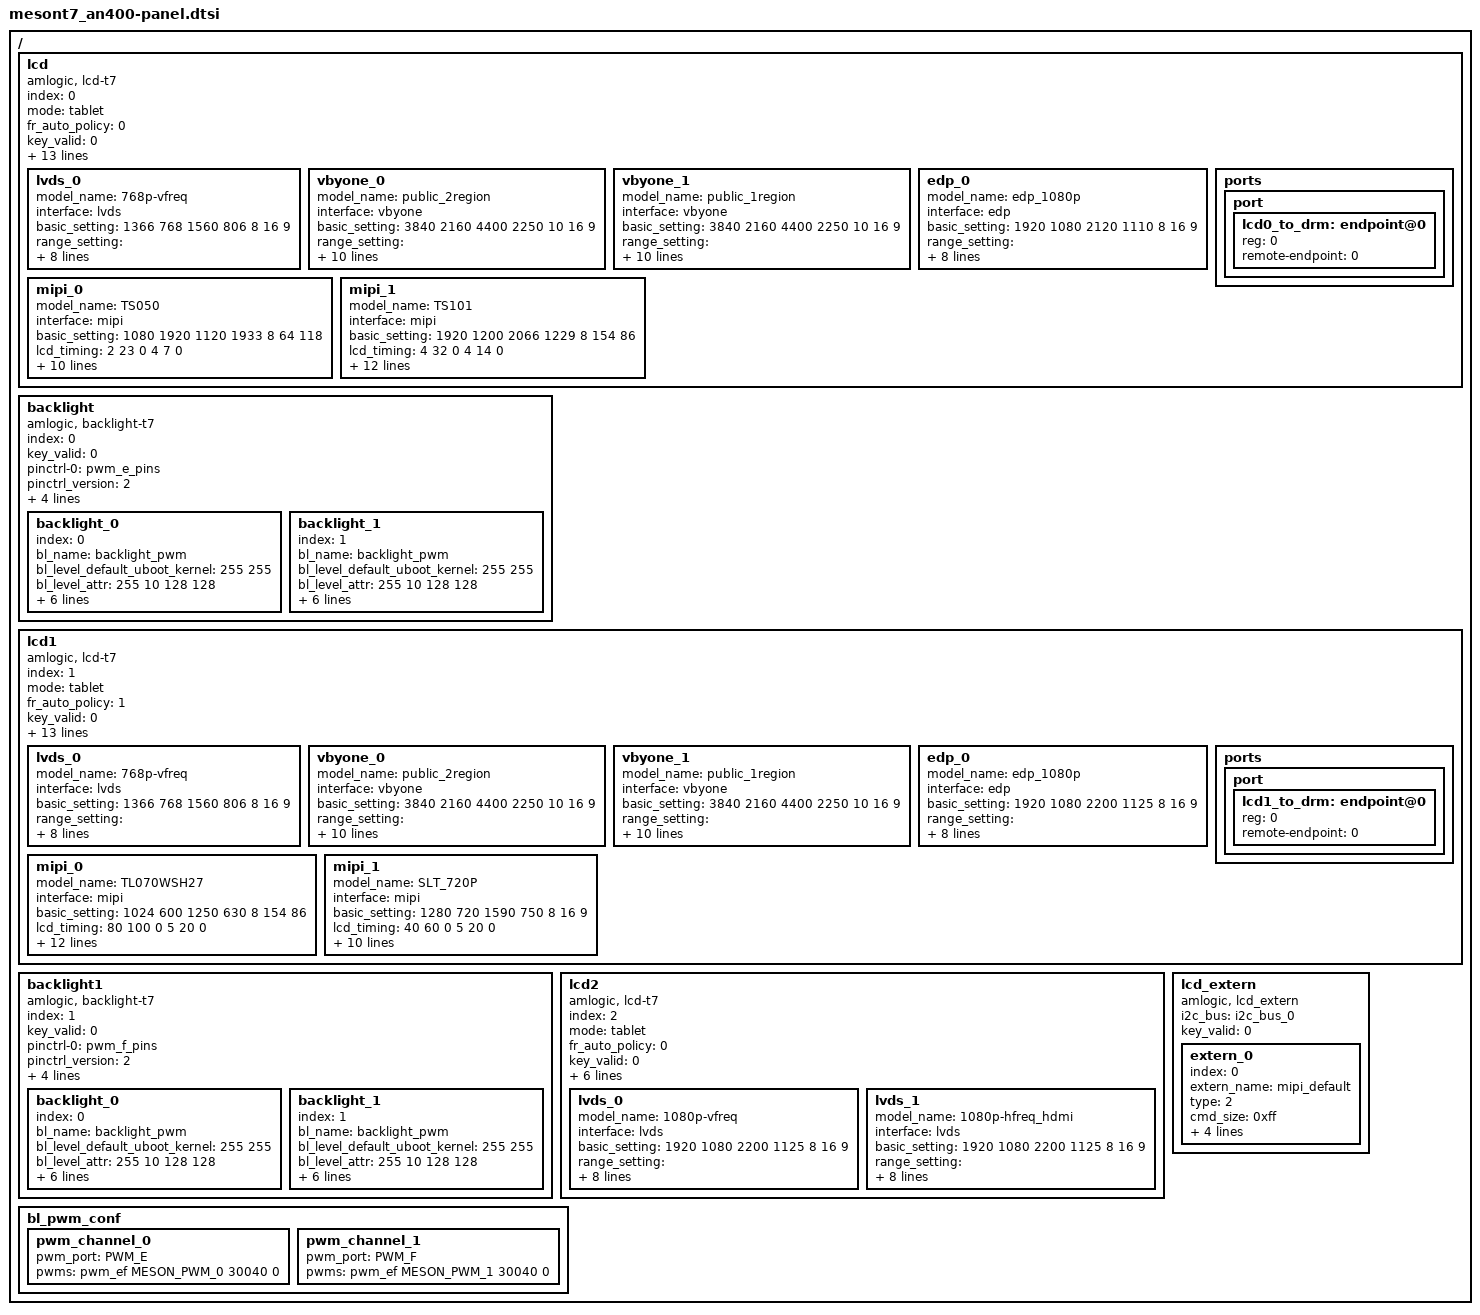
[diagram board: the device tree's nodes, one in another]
// SPDX-License-Identifier: (GPL-2.0+ OR MIT)
/*
 * Copyright (c) 2019 Amlogic, Inc. All rights reserved.
 */

/ {
	lcd:lcd {
		compatible = "amlogic, lcd-t7";
		status = "okay";
		index = <0>;
		mode = "tablet";
		fr_auto_policy = <0>; /* 0=disable, 1=60/50hz, 2=60/50/48hz */
		key_valid = <0>;
		clocks = <&clkc CLKID_MIPI_DSI_A
			&clkc CLKID_DSI0_PHY_GATE
			&clkc CLKID_DSI_A_MEAS_GATE>;
		clock-names = "dsi_host_gate",
			"dsi_phy_gate",
			"dsi_meas";
		reg = <0x0 0xfe018000 0x0 0x60     /* combo dphy */
			0x0 0xfe0b0000 0x0 0x10b0  /* edp_a host */
			0x0 0xfe074000 0x0 0x400   /* mipi_dsi_a host */
			0x0 0xfe014000 0x0 0x200   /* mipi_dsi_a phy */
			0x0 0xfe002000 0x0 0xa0    /* reset */
			0x0 0xfe004000 0x0 0x70>;  /* periphs */
		interrupts = <0 197 1
			0 194 1
			0 82 1
			0 282 1>;
		interrupt-names = "vsync","vsync2","vsync3","vbyone";
		pinctrl-names = "vbyone","vbyone_off","edp","edp_off";
		pinctrl-0 = <&lcd_vbyone_a_pins>;
		pinctrl-1 = <&lcd_vbyone_a_off_pins>;
		pinctrl-2 = <&lcd_edp_a_pins>;
		pinctrl-3 = <&lcd_edp_a_off_pins>;
		pinctrl_version = <2>; /* for uboot */

		/* power type:(0=cpu_gpio, 2=signal, 3=extern, 0xff=ending) */
		/* power index:(gpios_index, or extern_index, 0xff=invalid) */
		/* power value:(0=output low, 1=output high, 2=input) */
		/* power delay:(unit in ms) */
		lcd_cpu-gpios = <&gpio GPIOY_2 GPIO_ACTIVE_HIGH
			&gpio GPIOY_9 GPIO_ACTIVE_HIGH>;
		lcd_cpu_gpio_names = "GPIOY_2","GPIOY_9";

		lvds_0{
			model_name = "768p-vfreq";
			interface = "lvds"; /*lcd_interface(lvds, vbyone)*/
			basic_setting = <
				1366 768 /*h_active, v_active*/
				1560 806 /*h_period, v_period*/
				8      /*lcd_bits*/
				16 9>; /*screen_widht, screen_height*/
			range_setting = <
				1460 2000 /*h_period_min, max */
				784 1015  /*v_period_min, max */
				50000000 85000000>; /*pclk_min, max*/
			lcd_timing = <
				56 64 0   /*hs_width, hs_bp, hs_pol*/
				3  28 0>; /*vs_width, vs_bp, vs_pol*/
			clk_attr = <
				2 /*fr_adj_type
				   *(0=clk, 1=htotal, 2=vtotal, 3=auto_range,
				   * 4=hdmi_mode)
				   */
				15 /*clk_ss_level*/
				1 /*clk_auto_generate*/
				0>; /*pixel_clk(unit in Hz)*/
			lvds_attr = <
				1  /*lvds_repack*/
				0  /*dual_port*/
				0  /*pn_swap*/
				0  /*port_swap*/
				0>; /*lane_reverse*/
			phy_attr=<0x3 0>; /*vswing_level, preem_level*/

			/* power step: type, index, value, delay(ms) */
			power_on_step = <
				0 0 1 50  /*panel power on*/
				2 0 0 0   /*signal enable*/
				0xff 0 0 0>; /*ending*/
			power_off_step = <
				2 0 0 10  /*signal disable*/
				0 0 0 100 /*panel power off*/
				0xff 0 0 0>; /*ending*/
			backlight_index = <0xff>;
		};
		vbyone_0{
			model_name = "public_2region";
			interface = "vbyone"; /*lcd_interface(lvds, vbyone)*/
			basic_setting = <
				3840 2160 /*h_active, v_active*/
				4400 2250 /*h_period, v_period*/
				10     /*lcd_bits */
				16 9>; /*screen_widht, screen_height*/
			range_setting = <
				4240 4800 /*h_period_min, max*/
				2200 2760 /*v_period_min, max*/
				480000000 624000000>; /*pclk_min, max*/
			lcd_timing = <
				33 477 0  /*hs_width, hs_bp, hs_pol*/
				6  65 0>; /*vs_width, vs_bp, vs_pol*/
			clk_attr = <
				2 /*fr_adj_type
				   *(0=clk, 1=htotal, 2=vtotal, 3=auto_range,
				   * 4=hdmi_mode)
				   */
				0 /*clk_ss_level*/
				1 /*clk_auto_generate*/
				0>; /*pixel_clk(unit in Hz)*/
			vbyone_attr = <
				8 /*lane_count*/
				2 /*region_num*/
				4 /*byte_mode*/
				4>; /*color_fmt*/
			vbyone_intr_enable = <
				1 /*vbyone_intr_enable */
				3>; /*vbyone_vsync_intr_enable*/
			phy_attr=<0x7 1>; /* vswing_level, preem_level */
			hw_filter=<0 0>;  /* filter_time, filter_cnt*/

			/* power step: type, index, value, delay(ms) */
			power_on_step = <
				0 0 1 200  /*panel power on*/
				2 0 0 10  /*signal enable*/
				0xff 0 0 0>; /*ending*/
			power_off_step = <
				2 0 0 10 /*signal disable*/
				0 0 0 500 /*panel power off*/
				0xff 0 0 0>; /*ending*/
			backlight_index = <0>;
		};
		vbyone_1{
			model_name = "public_1region";
			interface = "vbyone"; /*lcd_interface(lvds, vbyone)*/
			basic_setting = <
				3840 2160 /*h_active, v_active*/
				4400 2250 /*h_period, v_period*/
				10     /*lcd_bits*/
				16 9>; /*screen_widht, screen_height*/
			range_setting = <
				4240 4800 /*h_period_min, max*/
				2200 2790 /*v_period_min, max*/
				552000000 632000000>; /*pclk_min,max*/
			lcd_timing = <
				33 477 0   /*hs_width, hs_bp, hs_pol*/
				6  65  0>; /*vs_width, vs_bp, vs_pol*/
			clk_attr = <
				2 /*fr_adj_type
				   *(0=clk, 1=htotal, 2=vtotal, 3=auto_range,
				   * 4=hdmi_mode)
				   */
				0 /*clk_ss_level*/
				1 /*clk_auto_generate*/
				0>; /*pixel_clk(unit in Hz)*/
			vbyone_attr = <
				8 /*lane_count*/
				1 /*region_num*/
				4 /*byte_mode*/
				4>; /*color_fmt*/
			vbyone_intr_enable = <
				1   /*vbyone_intr_enable*/
				3>; /*vbyone_vsync_intr_enable*/
			phy_attr=<0x7 1>; /* vswing_level, preem_level */
			hw_filter=<0 0>;  /* filter_time, filter_cnt*/

			/* power step: type, index, value, delay(ms) */
			power_on_step = <
				0 0 1 200  /*panel power on*/
				2 0 0 10 /*signal enable*/
				0xff 0 0 0>; /*ending*/
			power_off_step = <
				2 0 0 10  /*signal disable*/
				0 0 0 500 /*panel power off*/
				0xff 0 0 0>; /*ending*/
			backlight_index = <0xff>;
		};

		edp_0{
			model_name = "edp_1080p";
			interface = "edp"; /*lcd_interface(lvds, vbyone)*/
			basic_setting = <
				1920 1080 /*h_active, v_active*/
				2120 1110 /*h_period, v_period*/
				8      /*lcd_bits*/
				16 9>; /*screen_widht, screen_height*/
			range_setting = <
				2020 2400 /*h_period min, max*/
				1090 1200 /*v_period min, max*/
				132000000 142000000>; /*pclk_min, max*/
			lcd_timing = <
				20 80 0   /*hs_width, hs_bp, hs_pol*/
				10 10 0>; /*vs_width, vs_bp, vs_pol*/
			clk_attr = <
				0 /*fr_adj_type
				   *(0=clk, 1=htotal, 2=vtotal, 3=auto_range,
				   * 4=hdmi_mode)
				   */
				0 /*clk_ss_level */
				1 /*clk_auto_generate*/
				0>; /*pixel_clk(unit in Hz)*/
			edp_attr = <
				2 /*max_lane_count: 1,2,4*/
				1 /*max_link_rate: 0=1.62G, 1=2.7G*/
				0 /*training_mode*/
				0 /*edid_en, auto timing by edid*/
				0 /*reserved */
				0 /*reserved */
				0 /*reserved */
				0 /*reserved */
				0>; /*reserved*/
			phy_attr=<0x5 1>; /*vswing_level, preem_level*/

			/* power step: type, index, value, delay(ms) */
			power_on_step = <
				0 0 1 50  /*panel power on*/
				2 0 0 0   /*signal enable*/
				0xff 0 0 0>; /*ending*/
			power_off_step = <
				2 0 0 10  /*signal disable*/
				0 0 0 200  /*panel power on*/
				0xff 0 0 0>; /*ending*/
			backlight_index = <0x0>;
		};
		
		mipi_0{
			model_name = "TS050";
			interface = "mipi";
			basic_setting = <1080 1920 /*h_active, v_active*/
				1120 1933 /*h_period, v_period*/
				8 /*lcd_bits*/
				64 118>; /*screen_widht, screen_height*/
			lcd_timing = <2 23 0 /*hs_width, hs_bp, hs_pol*/
				4 7 0>; /*vs_width, vs_bp, vs_pol*/
			clk_attr = <0 /*fr_adj_type(0=clk, 1=htotal, 2=vtotal)*/
				0 /*clk_ss_level */
				1 /*clk_auto_generate*/
				120000000>; /*pixel_clk(unit in Hz)*/
			mipi_attr = <4 /*lane_num*/
				1000 /*bit_rate_max(MHz)*/
				0 /*factor(*100, default 0 for auto)*/
				1 /*operation_mode_init(0=video, 1=command)*/
				0 /*operation_mode_display(0=video, 1=command)*/
				2 /*
				   *video_mode_type
				   *(0=sync_pulse,1=sync_event,2=burst)
				   */
				1 /*clk_always_hs(0=disable,1=enable)*/
				0>; /*phy_switch(0=auto,1=standard,2=slow)*/

			/* dsi_init: data_type, num, data... */
			dsi_init_on = <0xff 0>;
			dsi_init_off = <0xff 0>;
			extern_init = <0x0>;
			/* power step: type, index, value, delay(ms) */
			power_on_step = <
				0 0 1 60
				0 1 1 20
				0 1 0 20
				0 1 1 20
				2 0 0 0
				0xff 0 0 0>; /*ending*/
			power_off_step = <
				2 0 0 0
				0 1 0 0
				0 0 0 20
				0xff 0 0 0>; /*ending*/
			backlight_index = <0>;
		};

		mipi_1{
			model_name = "TS101";
			interface = "mipi";
			basic_setting = <1920 1200 /*h_active, v_active*/
				2066 1229 /*h_period, v_period*/
				8 /*lcd_bits*/
				154 86>; /*screen_widht, screen_height*/
			lcd_timing = <4 32 0 /*hs_width, hs_bp, hs_pol*/
				4 14 0>; /*vs_width, vs_bp, vs_pol*/
			clk_attr = <0xff /*fr_adj_type(0=clk, 1=htotal, 2=vtotal)*/
				0 /*clk_ss_level */
				1 /*clk_auto_generate*/
				137112156>; /*pixel_clk(unit in Hz)*/
			mipi_attr = <4 /*lane_num*/
				1000 /*bit_rate_max(MHz)*/
				0 /*factor(*100, default 0 for auto)*/
				1 /*operation_mode_init(0=video, 1=command)*/
				0 /*operation_mode_display(0=video, 1=command)*/
				2 /*
				   *video_mode_type
				   *(0=sync_pulse,1=sync_event,2=burst)
				   */
				1 /*clk_always_hs(0=disable,1=enable)*/
				0>; /*phy_switch(0=auto,1=standard,2=slow)*/

			/* dsi_init: data_type, num, data... */
			dsi_init_on = <0x05 1 0x11
					0xfd 1 20     /*delay(ms)*/
					0x05 1 0x29
					0xfd 1 20     /*delay(ms)*/
					0xff 0>; /*ending*/
			dsi_init_off = <0x05 1 0x28
					0xfd 1 10     /*delay(ms)*/
					0x05 1 0x10
					0xfd 1 10     /*delay(ms)*/
					0xff 0>; /*ending*/
			extern_init = <0xff>; /*0xff for invalid*/

			/* power step: type, index, value, delay(ms) */
			power_on_step = <
				0 0 1 100
				0 1 0 10
				0 1 1 20
				2 0 0 0
				0xff 0 0 0>; /*ending*/
			power_off_step = <
				2 0 0 50
				0 1 0 10
				0 0 0 100
				0xff 0 0 0>; /*ending*/
			backlight_index = <0>;
		};

		ports {
			port {
				#address-cells = <1>;
				#size-cells = <0>;
				lcd0_to_drm: endpoint@0 {
					reg = <0>;
					remote-endpoint = <0>;
				};
			};
		};
	};

	backlight{
		compatible = "amlogic, backlight-t7";
		status = "okay";
		index = <0>;
		key_valid = <0>;
		pinctrl-names = "pwm_on";
		pinctrl-0 = <&pwm_e_pins>;
		pinctrl_version = <2>; /* for uboot */
		interrupts = <0 197 1
			0 194 1
			0 82 1>;
		interrupt-names = "vsync","vsync2","vsync3";
		bl_pwm_config = <&bl_pwm_conf>;

		/* pwm port: PWM_A, PWM_B, PWM_C, PWM_D, PWM_E, PWM_F, PWM_VS*/
		/* power index:(point gpios_index, 0xff=invalid) */
		/* power value:(0=output low, 1=output high, 2=input) */
		/* power delay:(unit in ms) */
		bl-gpios = <&gpio GPIOY_2 GPIO_ACTIVE_HIGH
			&gpio GPIOY_1 GPIO_ACTIVE_HIGH>;
		bl_gpio_names = "GPIOY_2","GPIOY_1";

		backlight_0{
			index = <0>;
			bl_name = "backlight_pwm";
			bl_level_default_uboot_kernel = <255 255>;
			bl_level_attr = <255 10 /*max, min*/
				128 128>; /*mid, mid_mapping*/
			bl_ctrl_method = <1>; /*1=pwm,2=pwm_combo*/
			bl_power_attr = <0 /*en_gpio_index*/
				1 0 /*on_value, off_value*/
				200 200>; /*on_delay(ms), off_delay(ms)*/
			bl_pwm_port = "PWM_E";
			bl_pwm_attr = <1 /*pwm_method(0=negative, 1=positvie)*/
				180 /*pwm_freq(pwm:Hz, pwm_vs:multiple of vs)*/
				100 25>; /*duty_max(%), duty_min(%)*/
			bl_pwm_power = <1 0 /*pwm_gpio_index, pwm_gpio_off*/
				10 10>; /*pwm_on_delay(ms), pwm_off_delay(ms)*/
			en_sequence_reverse = <0>; /* 1 for reverse */
		};

		backlight_1{
			index = <1>;
			bl_name = "backlight_pwm";
			bl_level_default_uboot_kernel = <255 255>;
			bl_level_attr = <255 10 /*max, min*/
				128 128>; /*mid, mid_mapping*/
			bl_ctrl_method = <1>; /*1=pwm,2=pwm_combo*/
			bl_power_attr = <0 /*en_gpio_index*/
				1 0 /*on_value, off_value*/
				200 200>; /*on_delay(ms), off_delay(ms)*/
			bl_pwm_port = "PWM_E";
			bl_pwm_attr = <0 /*pwm_method(0=negative, 1=positvie)*/
				180 /*pwm_freq(pwm:Hz, pwm_vs:multiple of vs)*/
				100 25>; /*duty_max(%), duty_min(%)*/
			bl_pwm_power = <1 0 /*pwm_gpio_index, pwm_gpio_off*/
				10 10>; /*pwm_on_delay(ms), pwm_off_delay(ms)*/
			en_sequence_reverse = <0>; /* 1 for reverse */
		};
	};

	lcd1:lcd1 {
		compatible = "amlogic, lcd-t7";
		status = "okay";
		index = <1>;
		mode = "tablet";
		fr_auto_policy = <1>; /* 0=disable, 1=60/50hz, 2=60/50/48hz */
		key_valid = <0>;
		clocks = <&clkc CLKID_MIPI_DSI_B
			&clkc CLKID_DSI1_PHY_GATE
			&clkc CLKID_DSI_B_MEAS_GATE>;
		clock-names = "dsi_host_gate",
			"dsi_phy_gate",
			"dsi_meas";
		reg = <0x0 0xfe018000 0x0 0x60     /* combo dphy */
			0x0 0xfe0b2000 0x0 0x10b0  /* edp_b host */
			0x0 0xfe072000 0x0 0x400   /* mipi_dsi_b host */
			0x0 0xfe016000 0x0 0x200   /* mipi_dsi_b phy */
			0x0 0xfe002000 0x0 0xa0    /* reset */
			0x0 0xfe004000 0x0 0x70>;  /* periphs */
		interrupts = <0 197 1
			0 194 1
			0 82 1
			0 283 1>;
		interrupt-names = "vsync","vsync2","vsync3","vbyone";
		pinctrl-names = "vbyone","vbyone_off","edp","edp_off";
		pinctrl-0 = <&lcd_vbyone_b_pins>;
		pinctrl-1 = <&lcd_vbyone_b_off_pins>;
		pinctrl-2 = <&lcd_edp_b_pins>;
		pinctrl-3 = <&lcd_edp_b_off_pins>;
		pinctrl_version = <2>; /* for uboot */

		/* power type:(0=cpu_gpio, 2=signal, 3=extern, 0xff=ending) */
		/* power index:(gpios_index, or extern_index, 0xff=invalid) */
		/* power value:(0=output low, 1=output high, 2=input) */
		/* power delay:(unit in ms) */
		lcd_cpu-gpios = <&gpio GPIOT_19 GPIO_ACTIVE_HIGH
			&gpio GPIOY_6 GPIO_ACTIVE_HIGH>;
		lcd_cpu_gpio_names = "GPIOT_19","GPIOY_6";

		lvds_0{
			model_name = "768p-vfreq";
			interface = "lvds"; /*lcd_interface(lvds, vbyone)*/
			basic_setting = <
				1366 768 /*h_active, v_active*/
				1560 806 /*h_period, v_period*/
				8      /*lcd_bits*/
				16 9>; /*screen_widht, screen_height*/
			range_setting = <
				1460 2000 /*h_period_min, max */
				784 1015  /*v_period_min, max */
				50000000 85000000>; /*pclk_min, max*/
			lcd_timing = <
				56 64 0   /*hs_width, hs_bp, hs_pol*/
				3  28 0>; /*vs_width, vs_bp, vs_pol*/
			clk_attr = <
				2 /*fr_adj_type
				   *(0=clk, 1=htotal, 2=vtotal, 3=auto_range,
				   * 4=hdmi_mode)
				   */
				15 /*clk_ss_level*/
				1 /*clk_auto_generate*/
				0>; /*pixel_clk(unit in Hz)*/
			lvds_attr = <
				1  /*lvds_repack*/
				0  /*dual_port*/
				0  /*pn_swap*/
				0  /*port_swap*/
				0>; /*lane_reverse*/
			phy_attr=<0x3 0>; /*vswing_level, preem_level*/

			/* power step: type, index, value, delay(ms) */
			power_on_step = <
				0 0 1 50  /*panel power on*/
				2 0 0 0   /*signal enable*/
				0xff 0 0 0>; /*ending*/
			power_off_step = <
				2 0 0 10  /*signal disable*/
				0 0 0 100 /*panel power off*/
				0xff 0 0 0>; /*ending*/
			backlight_index = <0xff>;
		};
		vbyone_0{
			model_name = "public_2region";
			interface = "vbyone"; /*lcd_interface(lvds, vbyone)*/
			basic_setting = <
				3840 2160 /*h_active, v_active*/
				4400 2250 /*h_period, v_period*/
				10     /*lcd_bits */
				16 9>; /*screen_widht, screen_height*/
			range_setting = <
				4240 4800 /*h_period_min, max*/
				2200 2760 /*v_period_min, max*/
				480000000 624000000>; /*pclk_min, max*/
			lcd_timing = <
				33 477 0  /*hs_width, hs_bp, hs_pol*/
				6  65 0>; /*vs_width, vs_bp, vs_pol*/
			clk_attr = <
				2 /*fr_adj_type
				   *(0=clk, 1=htotal, 2=vtotal, 3=auto_range,
				   * 4=hdmi_mode)
				   */
				0 /*clk_ss_level*/
				1 /*clk_auto_generate*/
				0>; /*pixel_clk(unit in Hz)*/
			vbyone_attr = <
				8 /*lane_count*/
				2 /*region_num*/
				4 /*byte_mode*/
				4>; /*color_fmt*/
			vbyone_intr_enable = <
				1 /*vbyone_intr_enable */
				3>; /*vbyone_vsync_intr_enable*/
			phy_attr=<0x7 1>; /* vswing_level, preem_level */
			hw_filter=<0 0>;  /* filter_time, filter_cnt*/

			/* power step: type, index, value, delay(ms) */
			power_on_step = <
				0 0 1 200  /*panel power on*/
				2 0 0 10  /*signal enable*/
				0xff 0 0 0>; /*ending*/
			power_off_step = <
				2 0 0 10 /*signal disable*/
				0 0 0 500  /*panel power off*/
				0xff 0 0 0>; /*ending*/
			backlight_index = <0x0>;
		};
		vbyone_1{
			model_name = "public_1region";
			interface = "vbyone"; /*lcd_interface(lvds, vbyone)*/
			basic_setting = <
				3840 2160 /*h_active, v_active*/
				4400 2250 /*h_period, v_period*/
				10     /*lcd_bits*/
				16 9>; /*screen_widht, screen_height*/
			range_setting = <
				4320 4800 /*h_period_min, max*/
				2200 2760 /*v_period_min, max*/
				503316480 654311424>; /*pclk_min,max*/
			lcd_timing = <
				33 477 0   /*hs_width, hs_bp, hs_pol*/
				6  65  0>; /*vs_width, vs_bp, vs_pol*/
			clk_attr = <
				2 /*fr_adj_type
				   *(0=clk, 1=htotal, 2=vtotal, 3=auto_range,
				   * 4=hdmi_mode)
				   */
				0 /*clk_ss_level*/
				1 /*clk_auto_generate*/
				0>; /*pixel_clk(unit in Hz)*/
			vbyone_attr = <
				8 /*lane_count*/
				1 /*region_num*/
				4 /*byte_mode*/
				4>; /*color_fmt*/
			vbyone_intr_enable = <
				1   /*vbyone_intr_enable*/
				3>; /*vbyone_vsync_intr_enable*/
			phy_attr=<0x7 1>; /* vswing_level, preem_level */
			hw_filter=<0 0>;  /* filter_time, filter_cnt*/

			/* power step: type, index, value, delay(ms) */
			power_on_step = <
				0 0 1 200  /*panel power on*/
				2 0 0 10 /*signal enable*/
				0xff 0 0 0>; /*ending*/
			power_off_step = <
				2 0 0 10  /*signal disable*/
				0 0 0 500  /*panel power off*/
				0xff 0 0 0>; /*ending*/
			backlight_index = <0x0>;
		};

		edp_0{
			model_name = "edp_1080p";
			interface = "edp"; /*lcd_interface(lvds, vbyone)*/
			basic_setting = <
				1920 1080 /*h_active, v_active*/
				2200 1125 /*h_period, v_period*/
				8      /*lcd_bits*/
				16 9>; /*screen_widht, screen_height*/
			range_setting = <
				2080 2720 /*h_period min, max*/
				1100 1380 /*v_period min, max*/
				133940000 156000000>; /*pclk_min, max*/
			lcd_timing = <
				44 148 0   /*hs_width, hs_bp, hs_pol*/
				5  30  0>; /*vs_width, vs_bp, vs_pol*/
			clk_attr = <
				0 /*fr_adj_type
				   *(0=clk, 1=htotal, 2=vtotal, 3=auto_range,
				   * 4=hdmi_mode)
				   */
				0 /*clk_ss_level */
				1 /*clk_auto_generate*/
				0>; /*pixel_clk(unit in Hz)*/
			edp_attr = <
				2 /*max_lane_count: 1,2,4*/
				1 /*max_link_rate: 0=1.62G, 1=2.7G*/
				0 /*training_mode*/
				0 /*reserved*/
				0 /*reserved */
				0 /*reserved */
				0 /*reserved */
				0 /*reserved */
				0>; /*reserved*/
			phy_attr=<0x5 1>; /*vswing_level, preem_level*/

			/* power step: type, index, value, delay(ms) */
			power_on_step = <
				0 0 1 50  /*panel power on*/
				2 0 0 0   /*signal enable*/
				0xff 0 0 0>; /*ending*/
			power_off_step = <
				2 0 0 10  /*signal disable*/
				0 0 0 200  /*panel power on*/
				0xff 0 0 0>; /*ending*/
			backlight_index = <0x0>;
		};
		mipi_0{
			model_name = "TL070WSH27";
			interface = "mipi";
			basic_setting = <1024 600 /*h_active, v_active*/
				1250 630 /*h_period, v_period*/
				8 /*lcd_bits*/
				154 86>; /*screen_widht, screen_height*/
			lcd_timing = <80 100 0 /*hs_width, hs_bp, hs_pol*/
				5 20 0>; /*vs_width, vs_bp, vs_pol*/
			clk_attr = <0 /*fr_adj_type(0=clk, 1=htotal, 2=vtotal)*/
				0 /*clk_ss_level */
				1 /*clk_auto_generate*/
				47250000>; /*pixel_clk(unit in Hz)*/
			mipi_attr = <4 /*lane_num*/
				300 /*bit_rate_max(MHz)*/
				0 /*factor(*100, default 0 for auto)*/
				1 /*operation_mode_init(0=video, 1=command)*/
				0 /*operation_mode_display(0=video, 1=command)*/
				2 /*
				   *video_mode_type
				   *(0=sync_pulse,1=sync_event,2=burst)
				   */
				1 /*clk_always_hs(0=disable,1=enable)*/
				0>; /*phy_switch(0=auto,1=standard,2=slow)*/

			/* dsi_init: data_type, num, data... */
			dsi_init_on = <0x05 1 0x11
					0xfd 1 20     /*delay(ms)*/
					0x05 1 0x29
					0xfd 1 20     /*delay(ms)*/
					0xff 0>; /*ending*/
			dsi_init_off = <0x05 1 0x28
					0xfd 1 10     /*delay(ms)*/
					0x05 1 0x10
					0xfd 1 10     /*delay(ms)*/
					0xff 0>; /*ending*/
			extern_init = <0xff>; /*0xff for invalid*/

			/* power step: type, index, value, delay(ms) */
			power_on_step = <
				0 0 1 100
				0 1 0 10
				0 1 1 20
				2 0 0 0
				0xff 0 0 0>; /*ending*/
			power_off_step = <
				2 0 0 50
				0 1 0 10
				0 0 0 100
				0xff 0 0 0>; /*ending*/
			backlight_index = <0x1>;
		};
		mipi_1{
			model_name = "SLT_720P";
			interface = "mipi";
			basic_setting = <1280 720 /*h_active, v_active*/
				1590 750 /*h_period, v_period*/
				8 /*lcd_bits*/
				16 9>; /*screen_widht, screen_height*/
			lcd_timing = <40 60 0 /*hs_width,hs_bp,hs_pol*/
				5 20 0>; /*vs_width,vs_bp,vs_pol*/
			clk_attr = <0 /*fr_adj_type(0=clock,1=htotal,2=vtotal)*/
				0 /*clk_ss_level*/
				1 /*clk_auto_generate*/
				74250000>; /*pixel_clk(unit in Hz)*/
			mipi_attr = <4 /*lane_num*/
				550 /*bit_rate_max(MHz)*/
				0 /*factor(*100, default 0 for auto)*/
				1 /*operation_mode_init(0=video, 1=command)*/
				0 /*operation_mode_display(0=video, 1=command)*/
				0 /*
				   *video_mode_type
				   *(0=sync_pulse,1=sync_event,2=burst)
				   */
				1 /*clk_always_hs(0=disable,1=enable)*/
				0>; /*phy_switch(0=auto,1=standard,2=slow)*/
				/* dsi_init: data_type, num, data... */
			dsi_init_on = <
				0x05 1 0x11
				0xff 200
				0x05 1 0x29
				0xff 20
				0xff 0xff>; /* ending flag */
			dsi_init_off = <
				0x05 1 0x28
				0xff 10
				0x05 1 0x10
				0xff 10
				0xff 0xff>; /* ending flag */
				/* extern_init: 0xff for invalid */
			extern_init = <0xff>;
				/* power step: type,index,value,delay(ms) */
			power_on_step = <
					3 7 0 100
					2 0 0 0
					0xff 0 0 0>;
			power_off_step = <
					2 0 0 0
					0xff 0 0 0>;
			backlight_index = <0xff>;
		};
		ports {
			port {
				#address-cells = <1>;
				#size-cells = <0>;
				lcd1_to_drm: endpoint@0 {
					reg = <0>;
					remote-endpoint = <0>;
				};
			};
		};
	};

	backlight1{
		compatible = "amlogic, backlight-t7";
		status = "okay";
		index = <1>;
		key_valid = <0>;
		pinctrl-names = "pwm_on";
		pinctrl-0 = <&pwm_f_pins>;
		pinctrl_version = <2>; /* for uboot */
		interrupts = <0 197 1
			0 194 1
			0 82 1>;
		interrupt-names = "vsync","vsync2","vsync3";
		bl_pwm_config = <&bl_pwm_conf>;

		/* pwm port: PWM_A, PWM_B, PWM_C, PWM_D, PWM_E, PWM_F, PWM_VS*/
		/* power index:(point gpios_index, 0xff=invalid) */
		/* power value:(0=output low, 1=output high, 2=input) */
		/* power delay:(unit in ms) */
		bl-gpios = <&gpio GPIOT_18 GPIO_ACTIVE_HIGH
			&gpio GPIOY_8 GPIO_ACTIVE_HIGH>;
		bl_gpio_names = "GPIOT_18","GPIOY_8";

		backlight_0{
			index = <0>;
			bl_name = "backlight_pwm";
			bl_level_default_uboot_kernel = <255 255>;
			bl_level_attr = <255 10 /*max, min*/
				128 128>; /*mid, mid_mapping*/
			bl_ctrl_method = <1>; /*1=pwm,2=pwm_combo*/
			bl_power_attr = <0 /*en_gpio_index*/
				1 0 /*on_value, off_value*/
				200 200>; /*on_delay(ms), off_delay(ms)*/
			bl_pwm_port = "PWM_F";
			bl_pwm_attr = <1 /*pwm_method(0=negative, 1=positvie)*/
				180 /*pwm_freq(pwm:Hz, pwm_vs:multiple of vs)*/
				100 25>; /*duty_max(%), duty_min(%)*/
			bl_pwm_power = <1 0 /*pwm_gpio_index, pwm_gpio_off*/
				10 10>; /*pwm_on_delay(ms), pwm_off_delay(ms)*/
			en_sequence_reverse = <0>; /* 1 for reverse */
		};

		backlight_1{
			index = <1>;
			bl_name = "backlight_pwm";
			bl_level_default_uboot_kernel = <255 255>;
			bl_level_attr = <255 10 /*max, min*/
				128 128>; /*mid, mid_mapping*/
			bl_ctrl_method = <1>; /*1=pwm,2=pwm_combo*/
			bl_power_attr = <0 /*en_gpio_index*/
				1 0 /*on_value, off_value*/
				200 200>; /*on_delay(ms), off_delay(ms)*/
			bl_pwm_port = "PWM_F";
			bl_pwm_attr = <0 /*pwm_method(0=negative, 1=positvie)*/
				180 /*pwm_freq(pwm:Hz, pwm_vs:multiple of vs)*/
				100 25>; /*duty_max(%), duty_min(%)*/
			bl_pwm_power = <1 0 /*pwm_gpio_index, pwm_gpio_off*/
				10 10>; /*pwm_on_delay(ms), pwm_off_delay(ms)*/
			en_sequence_reverse = <0>; /* 1 for reverse */
		};
	};

	lcd2:lcd2 {
		compatible = "amlogic, lcd-t7";
		status = "okay";
		index = <2>;
		mode = "tablet";
		fr_auto_policy = <0>; /* 0=disable, 1=60/50hz, 2=60/50/48hz */
		key_valid = <0>;
		reg = <0x0 0xfe018000 0x0 0x60     /* combo dphy */
			0x0 0xfe0b0000 0x0 0x10b0  /* edp_a host */
			0x0 0xfe074000 0x0 0x400   /* mipi_dsi_a host */
			0x0 0xfe014000 0x0 0x200   /* mipi_dsi_a phy */
			0x0 0xfe002000 0x0 0xa0    /* reset */
			0x0 0xfe004000 0x0 0x70>;  /* periphs */
		interrupts = <0 197 1
			0 194 1
			0 82 1>;
		interrupt-names = "vsync","vsync2","vsync3";
		pinctrl_version = <2>; /* for uboot */

		/* power type:(0=cpu_gpio, 2=signal, 3=extern, 0xff=ending) */
		/* power index:(gpios_index, or extern_index, 0xff=invalid) */
		/* power value:(0=output low, 1=output high, 2=input) */
		/* power delay:(unit in ms) */
		lcd_cpu-gpios = <&gpio GPIOY_14 GPIO_ACTIVE_HIGH>;
		lcd_cpu_gpio_names = "GPIOY_14";

		lvds_0{
			model_name = "1080p-vfreq";
			interface = "lvds"; /*lcd_interface(lvds, vbyone)*/
			basic_setting = <
				1920 1080 /*h_active, v_active*/
				2200 1125 /*h_period, v_period*/
				8      /*lcd_bits */
				16 9>; /*screen_widht, screen_height*/
			range_setting = <
				2060 2650  /*h_period_min,max*/
				1100 1480  /*v_period_min,max*/
				120000000 160000000>; /*pclk_min,max*/
			lcd_timing = <
				44 148 0  /*hs_width, hs_bp, hs_pol*/
				5  30 0>; /*vs_width, vs_bp, vs_pol*/
			clk_attr = <
				2 /*fr_adj_type
				   *(0=clk, 1=htotal, 2=vtotal, 3=auto_range,
				   * 4=hdmi_mode)
				   */
				0 /*clk_ss_level*/
				1 /*clk_auto_generate*/
				0>; /*pixel_clk(unit in Hz)*/
			lvds_attr = <
				1  /*lvds_repack*/
				1  /*dual_port*/
				0  /*pn_swap*/
				0  /*port_swap*/
				0>; /*lane_reverse*/
			phy_attr=<0x3 0>; /*vswing_level, preem_level*/

			/* power step: type, index, value, delay(ms) */
			power_on_step = <
				0 0 1 50  /*panel power on*/
				2 0 0 0   /*signal enable*/
				0xff 0 0 0>; /*ending*/
			power_off_step = <
				2 0 0 10  /*signal disable*/
				0 0 0 100  /*panel power off*/
				0xff 0 0 0>; /*ending*/
			backlight_index = <0xff>;
		};
		lvds_1{
			model_name = "1080p-hfreq_hdmi";
			interface = "lvds"; /*lcd_interface(lvds, vbyone)*/
			basic_setting = <
				1920 1080 /*h_active, v_active*/
				2200 1125 /*h_period, v_period*/
				8      /*lcd_bits*/
				16 9>; /*screen_widht, screen_height*/
			range_setting = <
				2080 2720 /*h_period min, max*/
				1100 1380 /*v_period min, max*/
				133940000 156000000>; /*pclk_min, max*/
			lcd_timing = <
				44 148 0   /*hs_width, hs_bp, hs_pol*/
				5  30  0>; /*vs_width, vs_bp, vs_pol*/
			clk_attr = <
				4 /*fr_adj_type
				   *(0=clk, 1=htotal, 2=vtotal, 3=auto_range,
				   * 4=hdmi_mode)
				   */
				0 /*clk_ss_level */
				1 /*clk_auto_generate*/
				0>; /*pixel_clk(unit in Hz)*/
			lvds_attr = <
				1 /*lvds_repack*/
				1 /*dual_port*/
				0 /*pn_swap*/
				0 /*port_swap*/
				0>; /*lane_reverse*/
			phy_attr=<0x3 0>; /*vswing_level, preem_level*/

			/* power step: type, index, value, delay(ms) */
			power_on_step = <
				0 0 1 50  /*panel power on*/
				2 0 0 0   /*signal enable*/
				0xff 0 0 0>; /*ending*/
			power_off_step = <
				2 0 0 10  /*signal disable*/
				0 0 0 100  /*panel power off*/
				0xff 0 0 0>; /*ending*/
			backlight_index = <0xff>;
		};
	};

	bl_pwm_conf:bl_pwm_conf{
		pwm_channel_0 {
			pwm_port = "PWM_E";
			pwms = <&pwm_ef MESON_PWM_0 30040 0>;
		};
		pwm_channel_1 {
			pwm_port = "PWM_F";
			pwms = <&pwm_ef MESON_PWM_1 30040 0>;
		};
	};
	
	lcd_extern{
		compatible = "amlogic, lcd_extern";
		status = "okay";
		i2c_bus = "i2c_bus_0";
		key_valid = <0>;

		extern_0{
			index = <0>;
			extern_name = "mipi_default";/*default*/
			status = "okay";
			type = <2>; /* 0=i2c, 1=spi, 2=mipi */
			cmd_size = <0xff>;
			init_on = <
				0x15 2	0xFF 0x05
				0x15 2	0xFB 0x01
				0x15 2	0xC5 0x01
				0xfd 1 120 /* delay 100ms */

				0x15 2 0xFF 0xEE
				0x15 2 0xFB 0x01
				0x15 2 0x1F 0x45
				0x15 2 0x24 0x4F
				0x15 2 0x38 0xC8
				0x15 2 0x39 0x27
				0x15 2 0x1E 0x77
				0x15 2 0x1D 0x0F
				0x15 2 0x7E 0x71
				0x15 2 0x7C 0x03
				0x15 2 0xFF 0x00
				0x15 2 0xFB 0x01
				0x15 2 0x35 0x01
				0x15 2 0xFF 0x01
				0x15 2 0xFB 0x01
				0x15 2 0x00 0x01
				0x15 2 0x01 0x55
				0x15 2 0x02 0x40
				0x15 2 0x05 0x40
				0x15 2 0x06 0x4A
				0x15 2 0x07 0x24
				0x15 2 0x08 0x0C
				0x15 2 0x0B 0x7D
				0x15 2 0x0C 0x7D
				0x15 2 0x0E 0xB0
				0x15 2 0x0F 0xAE
				0x15 2 0x11 0x10
				0x15 2 0x12 0x10
				0x15 2 0x13 0x03
				0x15 2 0x14 0x4A
				0x15 2 0x15 0x12
				0x15 2 0x16 0x12
				0x15 2 0x18 0x00
				0x15 2 0x19 0x77
				0x15 2 0x1A 0x55
				0x15 2 0x1B 0x13
				0x15 2 0x1C 0x00
				0x15 2 0x1D 0x00
				0x15 2 0x1E 0x13
				0x15 2 0x1F 0x00
				0x15 2 0x23 0x00
				0x15 2 0x24 0x00
				0x15 2 0x25 0x00
				0x15 2 0x26 0x00
				0x15 2 0x27 0x00
				0x15 2 0x28 0x00
				0x15 2 0x35 0x00
				0x15 2 0x66 0x00
				0x15 2 0x58 0x82
				0x15 2 0x59 0x02
				0x15 2 0x5A 0x02
				0x15 2 0x5B 0x02
				0x15 2 0x5C 0x82
				0x15 2 0x5D 0x82
				0x15 2 0x5E 0x02
				0x15 2 0x5F 0x02
				0x15 2 0x72 0x31
				0x15 2 0xFF 0x05
				0x15 2 0xFB 0x01
				0x15 2 0x00 0x01
				0x15 2 0x01 0x0B
				0x15 2 0x02 0x0C
				0x15 2 0x03 0x09
				0x15 2 0x04 0x0A
				0x15 2 0x05 0x00
				0x15 2 0x06 0x0F
				0x15 2 0x07 0x10
				0x15 2 0x08 0x00
				0x15 2 0x09 0x00
				0x15 2 0x0A 0x00
				0x15 2 0x0B 0x00
				0x15 2 0x0C 0x00
				0x15 2 0x0D 0x13
				0x15 2 0x0E 0x15
				0x15 2 0x0F 0x17
				0x15 2 0x10 0x01
				0x15 2 0x11 0x0B
				0x15 2 0x12 0x0C
				0x15 2 0x13 0x09
				0x15 2 0x14 0x0A
				0x15 2 0x15 0x00
				0x15 2 0x16 0x0F
				0x15 2 0x17 0x10
				0x15 2 0x18 0x00
				0x15 2 0x19 0x00
				0x15 2 0x1A 0x00
				0x15 2 0x1B 0x00
				0x15 2 0x1C 0x00
				0x15 2 0x1D 0x13
				0x15 2 0x1E 0x15
				0x15 2 0x1F 0x17
				0x15 2 0x20 0x00
				0x15 2 0x21 0x03
				0x15 2 0x22 0x01
				0x15 2 0x23 0x40
				0x15 2 0x24 0x40
				0x15 2 0x25 0xED
				0x15 2 0x29 0x58
				0x15 2 0x2A 0x12
				0x15 2 0x2B 0x01
				0x15 2 0x4B 0x06
				0x15 2 0x4C 0x11
				0x15 2 0x4D 0x20
				0x15 2 0x4E 0x02
				0x15 2 0x4F 0x02
				0x15 2 0x50 0x20
				0x15 2 0x51 0x61
				0x15 2 0x52 0x01
				0x15 2 0x53 0x63
				0x15 2 0x54 0x77
				0x15 2 0x55 0xED
				0x15 2 0x5B 0x00
				0x15 2 0x5C 0x00
				0x15 2 0x5D 0x00
				0x15 2 0x5E 0x00
				0x15 2 0x5F 0x15
				0x15 2 0x60 0x75
				0x15 2 0x61 0x00
				0x15 2 0x62 0x00
				0x15 2 0x63 0x00
				0x15 2 0x64 0x00
				0x15 2 0x65 0x00
				0x15 2 0x66 0x00
				0x15 2 0x67 0x00
				0x15 2 0x68 0x04
				0x15 2 0x69 0x00
				0x15 2 0x6A 0x00
				0x15 2 0x6C 0x40
				0x15 2 0x75 0x01
				0x15 2 0x76 0x01
				0x15 2 0x7A 0x80
				0x15 2 0x7B 0xA3
				0x15 2 0x7C 0xD8
				0x15 2 0x7D 0x60
				0x15 2 0x7F 0x15
				0x15 2 0x80 0x81
				0x15 2 0x83 0x05
				0x15 2 0x93 0x08
				0x15 2 0x94 0x10
				0x15 2 0x8A 0x00
				0x15 2 0x9B 0x0F
				0x15 2 0xEA 0xFF
				0x15 2 0xEC 0x00
				0x15 2 0xFF 0x01
				0x15 2 0xFB 0x01
				0x15 2 0x75 0x00
				0x15 2 0x76 0xDF
				0x15 2 0x77 0x00
				0x15 2 0x78 0xE4
				0x15 2 0x79 0x00
				0x15 2 0x7A 0xED
				0x15 2 0x7B 0x00
				0x15 2 0x7C 0xF6
				0x15 2 0x7D 0x00
				0x15 2 0x7E 0xFF
				0x15 2 0x7F 0x01
				0x15 2 0x80 0x07
				0x15 2 0x81 0x01
				0x15 2 0x82 0x10
				0x15 2 0x83 0x01
				0x15 2 0x84 0x18
				0x15 2 0x85 0x01
				0x15 2 0x86 0x20
				0x15 2 0x87 0x01
				0x15 2 0x88 0x3D
				0x15 2 0x89 0x01
				0x15 2 0x8A 0x56
				0x15 2 0x8B 0x01
				0x15 2 0x8C 0x84
				0x15 2 0x8D 0x01
				0x15 2 0x8E 0xAB
				0x15 2 0x8F 0x01
				0x15 2 0x90 0xEC
				0x15 2 0x91 0x02
				0x15 2 0x92 0x22
				0x15 2 0x93 0x02
				0x15 2 0x94 0x23
				0x15 2 0x95 0x02
				0x15 2 0x96 0x55
				0x15 2 0x97 0x02
				0x15 2 0x98 0x8B
				0x15 2 0x99 0x02
				0x15 2 0x9A 0xAF
				0x15 2 0x9B 0x02
				0x15 2 0x9C 0xDF
				0x15 2 0x9D 0x03
				0x15 2 0x9E 0x01
				0x15 2 0x9F 0x03
				0x15 2 0xA0 0x2C
				0x15 2 0xA2 0x03
				0x15 2 0xA3 0x39
				0x15 2 0xA4 0x03
				0x15 2 0xA5 0x47
				0x15 2 0xA6 0x03
				0x15 2 0xA7 0x56
				0x15 2 0xA9 0x03
				0x15 2 0xAA 0x66
				0x15 2 0xAB 0x03
				0x15 2 0xAC 0x76
				0x15 2 0xAD 0x03
				0x15 2 0xAE 0x85
				0x15 2 0xAF 0x03
				0x15 2 0xB0 0x90
				0x15 2 0xB1 0x03
				0x15 2 0xB2 0xCB
				0x15 2 0xB3 0x00
				0x15 2 0xB4 0xDF
				0x15 2 0xB5 0x00
				0x15 2 0xB6 0xE4
				0x15 2 0xB7 0x00
				0x15 2 0xB8 0xED
				0x15 2 0xB9 0x00
				0x15 2 0xBA 0xF6
				0x15 2 0xBB 0x00
				0x15 2 0xBC 0xFF
				0x15 2 0xBD 0x01
				0x15 2 0xBE 0x07
				0x15 2 0xBF 0x01
				0x15 2 0xC0 0x10
				0x15 2 0xC1 0x01
				0x15 2 0xC2 0x18
				0x15 2 0xC3 0x01
				0x15 2 0xC4 0x20
				0x15 2 0xC5 0x01
				0x15 2 0xC6 0x3D
				0x15 2 0xC7 0x01
				0x15 2 0xC8 0x56
				0x15 2 0xC9 0x01
				0x15 2 0xCA 0x84
				0x15 2 0xCB 0x01
				0x15 2 0xCC 0xAB
				0x15 2 0xCD 0x01
				0x15 2 0xCE 0xEC
				0x15 2 0xCF 0x02
				0x15 2 0xD0 0x22
				0x15 2 0xD1 0x02
				0x15 2 0xD2 0x23
				0x15 2 0xD3 0x02
				0x15 2 0xD4 0x55
				0x15 2 0xD5 0x02
				0x15 2 0xD6 0x8B
				0x15 2 0xD7 0x02
				0x15 2 0xD8 0xAF
				0x15 2 0xD9 0x02
				0x15 2 0xDA 0xDF
				0x15 2 0xDB 0x03
				0x15 2 0xDC 0x01
				0x15 2 0xDD 0x03
				0x15 2 0xDE 0x2C
				0x15 2 0xDF 0x03
				0x15 2 0xE0 0x39
				0x15 2 0xE1 0x03
				0x15 2 0xE2 0x47
				0x15 2 0xE3 0x03
				0x15 2 0xE4 0x56
				0x15 2 0xE5 0x03
				0x15 2 0xE6 0x66
				0x15 2 0xE7 0x03
				0x15 2 0xE8 0x76
				0x15 2 0xE9 0x03
				0x15 2 0xEA 0x85
				0x15 2 0xEB 0x03
				0x15 2 0xEC 0x90
				0x15 2 0xED 0x03
				0x15 2 0xEE 0xCB
				0x15 2 0xEF 0x00
				0x15 2 0xF0 0xBB
				0x15 2 0xF1 0x00
				0x15 2 0xF2 0xC0
				0x15 2 0xF3 0x00
				0x15 2 0xF4 0xCC
				0x15 2 0xF5 0x00
				0x15 2 0xF6 0xD6
				0x15 2 0xF7 0x00
				0x15 2 0xF8 0xE1
				0x15 2 0xF9 0x00
				0x15 2 0xFA 0xEA
				0x15 2 0xFF 0x02
				0x15 2 0xFB 0x01
				0x15 2 0x00 0x00
				0x15 2 0x01 0xF4
				0x15 2 0x02 0x00
				0x15 2 0x03 0xEF
				0x15 2 0x04 0x01
				0x15 2 0x05 0x07
				0x15 2 0x06 0x01
				0x15 2 0x07 0x28
				0x15 2 0x08 0x01
				0x15 2 0x09 0x44
				0x15 2 0x0A 0x01
				0x15 2 0x0B 0x76
				0x15 2 0x0C 0x01
				0x15 2 0x0D 0xA0
				0x15 2 0x0E 0x01
				0x15 2 0x0F 0xE7
				0x15 2 0x10 0x02
				0x15 2 0x11 0x1F
				0x15 2 0x12 0x02
				0x15 2 0x13 0x22
				0x15 2 0x14 0x02
				0x15 2 0x15 0x54
				0x15 2 0x16 0x02
				0x15 2 0x17 0x8B
				0x15 2 0x18 0x02
				0x15 2 0x19 0xAF
				0x15 2 0x1A 0x02
				0x15 2 0x1B 0xE0
				0x15 2 0x1C 0x03
				0x15 2 0x1D 0x01
				0x15 2 0x1E 0x03
				0x15 2 0x1F 0x2D
				0x15 2 0x20 0x03
				0x15 2 0x21 0x39
				0x15 2 0x22 0x03
				0x15 2 0x23 0x47
				0x15 2 0x24 0x03
				0x15 2 0x25 0x57
				0x15 2 0x26 0x03
				0x15 2 0x27 0x65
				0x15 2 0x28 0x03
				0x15 2 0x29 0x77
				0x15 2 0x2A 0x03
				0x15 2 0x2B 0x85
				0x15 2 0x2D 0x03
				0x15 2 0x2F 0x8F
				0x15 2 0x30 0x03
				0x15 2 0x31 0xCB
				0x15 2 0x32 0x00
				0x15 2 0x33 0xBB
				0x15 2 0x34 0x00
				0x15 2 0x35 0xC0
				0x15 2 0x36 0x00
				0x15 2 0x37 0xCC
				0x15 2 0x38 0x00
				0x15 2 0x39 0xD6
				0x15 2 0x3A 0x00
				0x15 2 0x3B 0xE1
				0x15 2 0x3D 0x00
				0x15 2 0x3F 0xEA
				0x15 2 0x40 0x00
				0x15 2 0x41 0xF4
				0x15 2 0x42 0x00
				0x15 2 0x43 0xFE
				0x15 2 0x44 0x01
				0x15 2 0x45 0x07
				0x15 2 0x46 0x01
				0x15 2 0x47 0x28
				0x15 2 0x48 0x01
				0x15 2 0x49 0x44
				0x15 2 0x4A 0x01
				0x15 2 0x4B 0x76
				0x15 2 0x4C 0x01
				0x15 2 0x4D 0xA0
				0x15 2 0x4E 0x01
				0x15 2 0x4F 0xE7
				0x15 2 0x50 0x02
				0x15 2 0x51 0x1F
				0x15 2 0x52 0x02
				0x15 2 0x53 0x22
				0x15 2 0x54 0x02
				0x15 2 0x55 0x54
				0x15 2 0x56 0x02
				0x15 2 0x58 0x8B
				0x15 2 0x59 0x02
				0x15 2 0x5A 0xAF
				0x15 2 0x5B 0x02
				0x15 2 0x5C 0xE0
				0x15 2 0x5D 0x03
				0x15 2 0x5E 0x01
				0x15 2 0x5F 0x03
				0x15 2 0x60 0x2D
				0x15 2 0x61 0x03
				0x15 2 0x62 0x39
				0x15 2 0x63 0x03
				0x15 2 0x64 0x47
				0x15 2 0x65 0x03
				0x15 2 0x66 0x57
				0x15 2 0x67 0x03
				0x15 2 0x68 0x65
				0x15 2 0x69 0x03
				0x15 2 0x6A 0x77
				0x15 2 0x6B 0x03
				0x15 2 0x6C 0x85
				0x15 2 0x6D 0x03
				0x15 2 0x6E 0x8F
				0x15 2 0x6F 0x03
				0x15 2 0x70 0xCB
				0x15 2 0x71 0x00
				0x15 2 0x72 0x00
				0x15 2 0x73 0x00
				0x15 2 0x74 0x21
				0x15 2 0x75 0x00
				0x15 2 0x76 0x4C
				0x15 2 0x77 0x00
				0x15 2 0x78 0x6B
				0x15 2 0x79 0x00
				0x15 2 0x7A 0x85
				0x15 2 0x7B 0x00
				0x15 2 0x7C 0x9A
				0x15 2 0x7D 0x00
				0x15 2 0x7E 0xAD
				0x15 2 0x7F 0x00
				0x15 2 0x80 0xBE
				0x15 2 0x81 0x00
				0x15 2 0x82 0xCD
				0x15 2 0x83 0x01
				0x15 2 0x84 0x01
				0x15 2 0x85 0x01
				0x15 2 0x86 0x29
				0x15 2 0x87 0x01
				0x15 2 0x88 0x68
				0x15 2 0x89 0x01
				0x15 2 0x8A 0x98
				0x15 2 0x8B 0x01
				0x15 2 0x8C 0xE5
				0x15 2 0x8D 0x02
				0x15 2 0x8E 0x1E
				0x15 2 0x8F 0x02
				0x15 2 0x90 0x30
				0x15 2 0x91 0x02
				0x15 2 0x92 0x52
				0x15 2 0x93 0x02
				0x15 2 0x94 0x88
				0x15 2 0x95 0x02
				0x15 2 0x96 0xAA
				0x15 2 0x97 0x02
				0x15 2 0x98 0xD7
				0x15 2 0x99 0x02
				0x15 2 0x9A 0xF7
				0x15 2 0x9B 0x03
				0x15 2 0x9C 0x21
				0x15 2 0x9D 0x03
				0x15 2 0x9E 0x2E
				0x15 2 0x9F 0x03
				0x15 2 0xA0 0x3D
				0x15 2 0xA2 0x03
				0x15 2 0xA3 0x4C
				0x15 2 0xA4 0x03
				0x15 2 0xA5 0x5E
				0x15 2 0xA6 0x03
				0x15 2 0xA7 0x71
				0x15 2 0xA9 0x03
				0x15 2 0xAA 0x86
				0x15 2 0xAB 0x03
				0x15 2 0xAC 0x94
				0x15 2 0xAD 0x03
				0x15 2 0xAE 0xFA
				0x15 2 0xAF 0x00
				0x15 2 0xB0 0x00
				0x15 2 0xB1 0x00
				0x15 2 0xB2 0x21
				0x15 2 0xB3 0x00
				0x15 2 0xB4 0x4C
				0x15 2 0xB5 0x00
				0x15 2 0xB6 0x6B
				0x15 2 0xB7 0x00
				0x15 2 0xB8 0x85
				0x15 2 0xB9 0x00
				0x15 2 0xBA 0x9A
				0x15 2 0xBB 0x00
				0x15 2 0xBC 0xAD
				0x15 2 0xBD 0x00
				0x15 2 0xBE 0xBE
				0x15 2 0xBF 0x00
				0x15 2 0xC0 0xCD
				0x15 2 0xC1 0x01
				0x15 2 0xC2 0x01
				0x15 2 0xC3 0x01
				0x15 2 0xC4 0x29
				0x15 2 0xC5 0x01
				0x15 2 0xC6 0x68
				0x15 2 0xC7 0x01
				0x15 2 0xC8 0x98
				0x15 2 0xC9 0x01
				0x15 2 0xCA 0xE5
				0x15 2 0xCB 0x02
				0x15 2 0xCC 0x1E
				0x15 2 0xCD 0x02
				0x15 2 0xCE 0x20
				0x15 2 0xCF 0x02
				0x15 2 0xD0 0x52
				0x15 2 0xD1 0x02
				0x15 2 0xD2 0x88
				0x15 2 0xD3 0x02
				0x15 2 0xD4 0xAA
				0x15 2 0xD5 0x02
				0x15 2 0xD6 0xD7
				0x15 2 0xD7 0x02
				0x15 2 0xD8 0xF7
				0x15 2 0xD9 0x03
				0x15 2 0xDA 0x21
				0x15 2 0xDB 0x03
				0x15 2 0xDC 0x2E
				0x15 2 0xDD 0x03
				0x15 2 0xDE 0x3D
				0x15 2 0xDF 0x03
				0x15 2 0xE0 0x4C
				0x15 2 0xE1 0x03
				0x15 2 0xE2 0x5E
				0x15 2 0xE3 0x03
				0x15 2 0xE4 0x71
				0x15 2 0xE5 0x03
				0x15 2 0xE6 0x86
				0x15 2 0xE7 0x03
				0x15 2 0xE8 0x94
				0x15 2 0xE9 0x03
				0x15 2 0xEA 0xFA
				0x15 2 0xFF 0x01
				0x15 2 0xFB 0x01
				0x15 2 0xFF 0x02
				0x15 2 0xFB 0x01
				0x15 2 0xFF 0x04
				0x15 2 0xFB 0x01
				0x15 2 0xFF 0x00
				0x15 2 0xD3 0x0b
				0x15 2 0xD4 0x04

				0x05 1 0x11
				0xfd 1 120 /* delay 120ms */

				0x15 2 0xFF 0x00
				0x15 2 0x35 0x00
				0x05 1 0x29
				0xfd 1 10   /* delay 10ms */
				0xFF 0>;   /*ending*/
			init_off = <
				0x05 1 0x28 /* display off */
				0xfd 1 10   /* delay 10ms */
				0x05 1 0x10 /* sleep in */
				0xfd 1 150  /* delay 150ms */
				0xff 0>;    /*ending*/
		};
	};

}; /* end of / */
